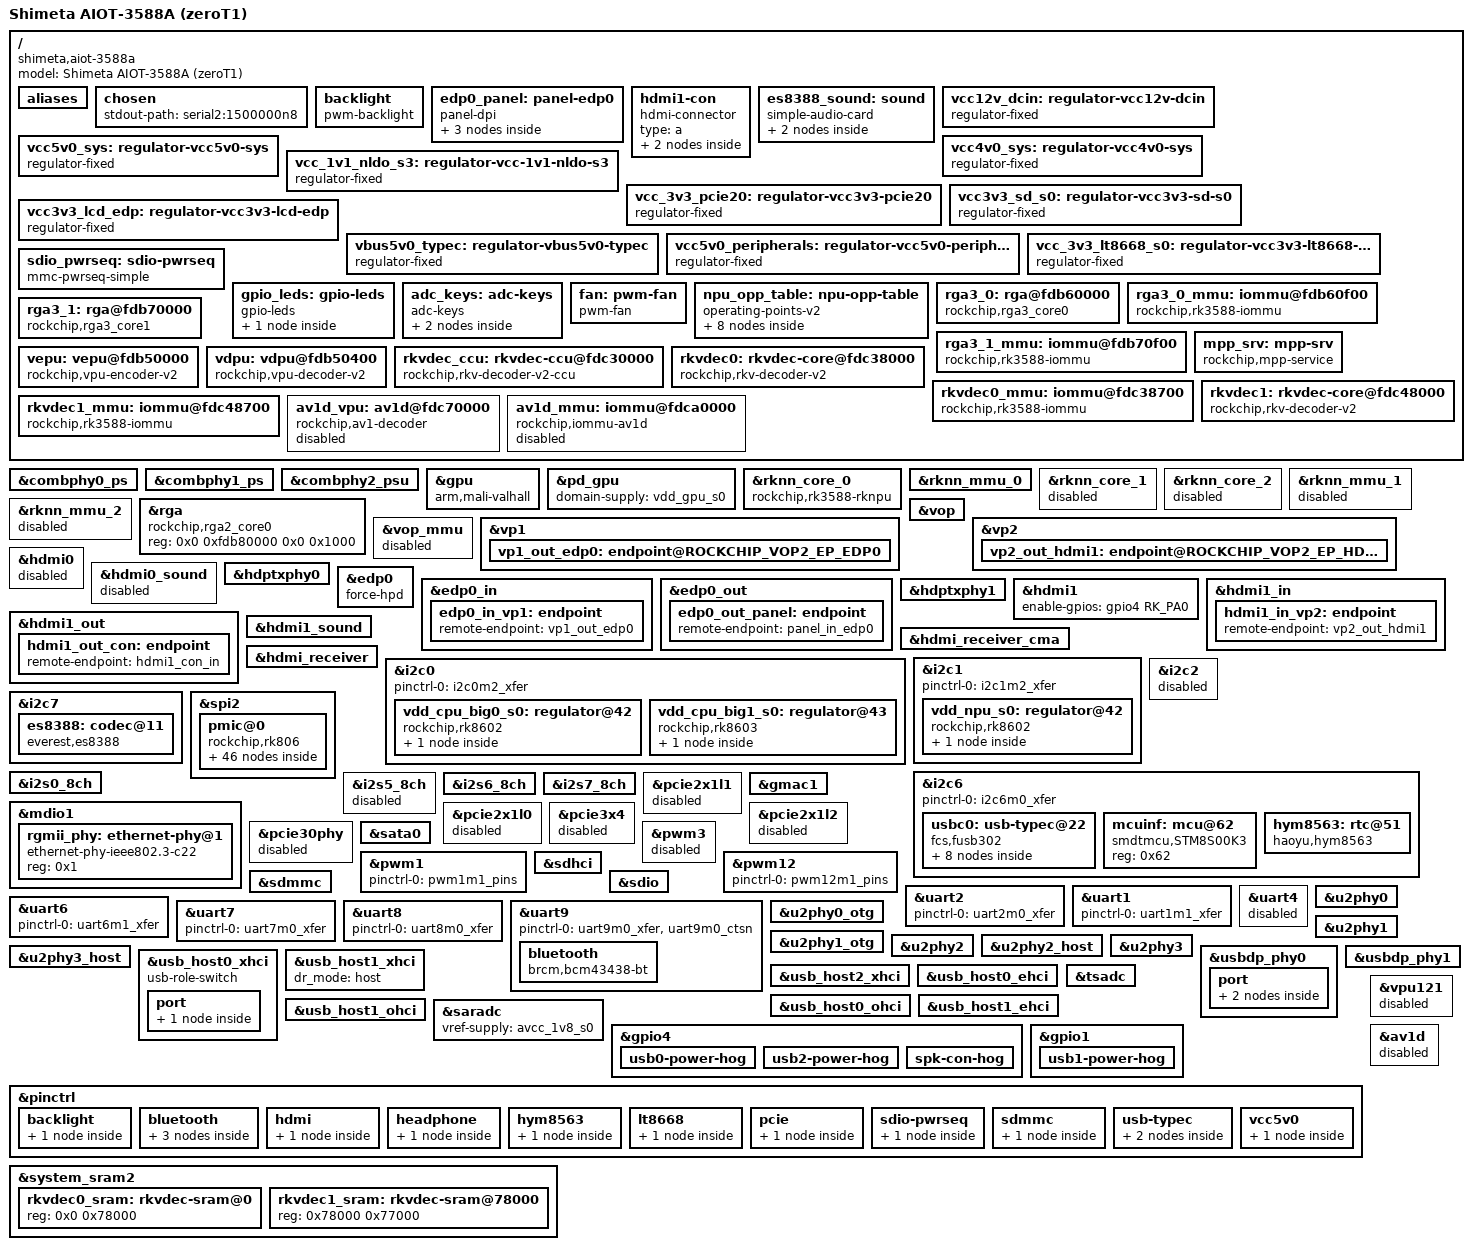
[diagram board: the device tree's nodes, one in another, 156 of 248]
// SPDX-License-Identifier: (GPL-2.0+ OR MIT)
/*
 * Shimeta（视美泰）AIOT-3588A / zeroT1 —— RK3588 板级设备树（fnOS / 上游内核版）
 *
 * 底稿：FriendlyElec NanoPC-T6 上游 DTS（Linux v6.18 的
 *       arch/arm64/boot/dts/rockchip/rk3588-nanopc-t6.dtsi），按硬件差异裁剪移植。
 *       引脚、GPIO、电源、面板时序等硬件事实取自视美泰原厂 2023 固件反编译树
 *       （RK BSP 6.1 的 rk3588-aiot3588a.dts），写法遵循上游 mainline 6.18。
 *
 * 与 NanoPC-T6 的主要差异（也是为什么不能直接用 nanopc-t6.dtb）：
 *  1. 主显示是 eDP 面板（1920x1080，139MHz / 2080x1111 厂商时序，实机刷新率
 *     60.15Hz；VOP dclk 实测 136.36MHz，详见 panel-timing 注释），不是 HDMI0：
 *     - eDP PHY = hdptxphy0（fed60000），HDMI0 与 eDP 共用这一颗 PHY，本板未用 HDMI0
 *     - eDP 控制器 edp0 -> VOP VP1；HDMI1 -> VOP VP2（不能走 VP0，理由见下）
 *     - 面板：GPIO2_C5 使能，vcc3v3_lcd_edp 供电，PWM1 背光（GPIO2_C1 使能，周期 20000ns）
 *  2. HDMI 输出走 HDMI1（hdptxphy1 / fed70000，GPIO4_A0 使能）-> VOP **VP2**
 *     - 2026-11-02 实测：HDMI1 走 VP0 时，只要 eDP 同时启用（eDP 占 VP1），
 *       HDMI 侧 PHY/时钟全部正常但显示器黑屏；改接 VP2 后双屏同时输出正常。
 *       （只开 eDP、HDMI 不接时 VP0 也能亮，属视频口复用冲突，不能作为定论。）
 *  3. HDMI IN：hdmi_receiver（fdee0000），HPD 检测脚 GPIO1_PD5
 *  4. 音频 codec 是 ES8388（i2c7 0x1b，i2s0_8ch），耳机检测 GPIO4_C2，
 *     扬声器功放使能 GPIO4_A3（低有效，用 gpio-hog 常开）
 *  5. WiFi/BT 是 AP6256：WiFi 走 SDIO（sdio_pwrseq GPIO0_PC4 复位），
 *     BT 走 uart9（reset GPIO0_PC6 / wake GPIO0_PC5 / host-wake GPIO0_PA0）
 *  6. 电源域不同：CPU 大核 i2c0（rk8602@42 / rk8603@43），NPU 在 i2c1（rk8602@42）
 *  7. 板载 SATA0（combphy0_ps）+ miniPCIe（pcie2x1l1 / fe180000 / combphy1_ps，
 *     reset GPIO1_PA7），2230 NVMe SSD 与 4G 模块共用 miniPCIe 座的不同通道
 *  8. 5 路业务串口：uart1/uart4/uart6/uart7/uart8（+ uart9 给蓝牙，uart2 调试）
 *  9. 板级电源：vcc5v0_peripherals（GPIO3_D5，必须 always-on）、
 *     vcc_3v3_lt8668_s0（GPIO4_PB6，HDMI 输出芯片供电，always-on）
 * 10. 无 IR 接收（原厂用 pwm3 的 remotectl 驱动，上游没有该驱动，此 DTS 未启用）
 *
 * 编译方式：作为 mainline 内核 arch/arm64/boot/dts/rockchip/ 下的文件，
 *   在 Makefile 的 dtb-y 里加 rk3588-aiot3588a.dtb 即可，随内核一起编译。
 */

/dts-v1/;

#include <dt-bindings/gpio/gpio.h>
#include <dt-bindings/input/input.h>
#include <dt-bindings/pinctrl/rockchip.h>
#include <dt-bindings/pwm/pwm.h>
#include <dt-bindings/soc/rockchip,vop2.h>
#include <dt-bindings/usb/pd.h>
#include "rk3588.dtsi"

/ {
	model = "Shimeta AIOT-3588A (zeroT1)";
	compatible = "shimeta,aiot-3588a", "rockchip,rk3588";

	aliases {
		mmc0 = &sdhci;
		mmc1 = &sdmmc;
		mmc2 = &sdio;
		/* 厂商 mpp_rkvdec2 驱动用 of_alias_get_id(np, "rkvdec") 取 core_id，
		 * core0 才会注册进 mpp service，所以别名必须有 */
		rkvdec0 = &rkvdec0;
		rkvdec1 = &rkvdec1;
	};

	chosen {
		stdout-path = "serial2:1500000n8";
	};

	/* ==================== 显示 ==================== */

	backlight: backlight {
		compatible = "pwm-backlight";
		pwms = <&pwm1 0 20000 0>;
		brightness-levels = <0 20 40 60 80 100 120 140 160 180 200 220 240 255>;
		default-brightness-level = <7>;
		enable-gpios = <&gpio2 RK_PC1 GPIO_ACTIVE_HIGH>;
		pinctrl-names = "default";
		pinctrl-0 = <&backlight_en>;
		status = "okay";
	};

	/*
	 * eDP 面板。fnOS 用的 mainline 6.18 内核里 panel-simple 驱动
	 * 已经删掉了通用 "simple-panel" compatible（只剩 "panel-dpi"），
	 * 且 eDP connector-type 会被显式拒绝（"eDP panels moved to panel-edp"）。
	 * 因此这里用 "panel-dpi"：panel_dpi_probe() 从 panel-timing 解析时序、
	 * connector 类型固定为 DPI（对 VOP->eDP 链路无影响，eDP connector 由
	 * rockchip-dp 自己创建），panel-simple 能正常 bind 并注册 drm_panel。
	 */
	edp0_panel: panel-edp0 {
		compatible = "panel-dpi";
		backlight = <&backlight>;
		power-supply = <&vcc3v3_lcd_edp>;
		enable-gpios = <&gpio2 RK_PC5 GPIO_ACTIVE_HIGH>;
		prepare-delay-ms = <120>;
		enable-delay-ms = <120>;
		unprepare-delay-ms = <120>;
		disable-delay-ms = <120>;
		width-mm = <129>;
		height-mm = <171>;
		bpc = <8>;
		status = "okay";

		panel-timing {
			/* 139MHz / 2080x1111 —— 面板厂商标称时序，2026-11-11 实机验证画面
			 * 正常，面板侧刷新率 60.15Hz（此前 132MHz 方案只有 57.12Hz）。
			 *
			 * VOP dclk 只能从 PLL 整数分频：实测 dclk_vop1 = 136.36MHz
			 * （1500MHz/11），并非精确 139MHz；但面板 TCON 按该时序工作正常。
			 * 历史：曾担心 VOP/TRX 的 MSA 时钟与实际像素时钟不一致，先用
			 * 132MHz（GPLL 1188/9）验证；也试过 132MHz/2000x1100（恰好 60Hz）
			 * —— 屏幕不出图，TCON 不接受该 porch。
			 * ⇒ clock-frequency 按标称 139MHz 写；porch 必须保持 2080x1111，
			 *   不要为凑刷新率改动。
			 */
			clock-frequency = <139000000>;
			hactive = <1920>;
			vactive = <1080>;
			hfront-porch = <40>;
			hsync-len = <20>;
			hback-porch = <100>;
			vfront-porch = <12>;
			vsync-len = <4>;
			vback-porch = <15>;
			hsync-active = <0>;
			vsync-active = <0>;
			de-active = <0>;
			pixelclk-active = <0>;
		};

		port {
			panel_in_edp0: endpoint {
				remote-endpoint = <&edp0_out_panel>;
			};
		};
	};

	hdmi1-con {
		compatible = "hdmi-connector";
		type = "a";

		port {
			hdmi1_con_in: endpoint {
				remote-endpoint = <&hdmi1_out_con>;
			};
		};
	};

	/* ==================== 音频 ==================== */

	es8388_sound: sound {
		compatible = "simple-audio-card";
		simple-audio-card,name = "rockchip-es8388";
		simple-audio-card,format = "i2s";
		simple-audio-card,mclk-fs = <256>;
		simple-audio-card,hp-det-gpios = <&gpio4 RK_PC2 GPIO_ACTIVE_HIGH>;
		pinctrl-names = "default";
		pinctrl-0 = <&hp_det>;
		/*
		 * es8328 驱动的 DAPM widget 只有 Headphone/Speaker 与
		 * LINPUT1/2、RINPUT1/2，没有 "Main Mic"/"MIC1" 这类名字；
		 * 写错会让 simple-audio-card 解析失败、整张声卡注册不了
		 * （日志：Failed to add route MIC1(*) -> Main Mic / -ENODEV）。
		 * 本板 NAS 场景只用播放，麦克风路由先不写。
		 */
		simple-audio-card,widgets =
			"Headphone", "Headphones",
			"Speaker", "Speaker";
		simple-audio-card,routing =
			"Headphones", "LOUT1",
			"Headphones", "ROUT1",
			"Speaker", "LOUT2",
			"Speaker", "ROUT2";

		simple-audio-card,cpu {
			sound-dai = <&i2s0_8ch>;
		};

		simple-audio-card,codec {
			sound-dai = <&es8388>;
		};
	};

	/* ==================== 电源 ==================== */

	vcc12v_dcin: regulator-vcc12v-dcin {
		compatible = "regulator-fixed";
		regulator-name = "vcc12v_dcin";
		regulator-always-on;
		regulator-boot-on;
		regulator-min-microvolt = <12000000>;
		regulator-max-microvolt = <12000000>;
	};

	/* vcc5v0_sys 供外设 */
	vcc5v0_sys: regulator-vcc5v0-sys {
		compatible = "regulator-fixed";
		regulator-name = "vcc5v0_sys";
		regulator-always-on;
		regulator-boot-on;
		regulator-min-microvolt = <5000000>;
		regulator-max-microvolt = <5000000>;
		vin-supply = <&vcc12v_dcin>;
	};

	/* vcc4v0_sys 供 RK806 / RK860x */
	vcc4v0_sys: regulator-vcc4v0-sys {
		compatible = "regulator-fixed";
		regulator-name = "vcc4v0_sys";
		regulator-always-on;
		regulator-boot-on;
		regulator-min-microvolt = <4000000>;
		regulator-max-microvolt = <4000000>;
		vin-supply = <&vcc12v_dcin>;
	};

	vcc_1v1_nldo_s3: regulator-vcc-1v1-nldo-s3 {
		compatible = "regulator-fixed";
		regulator-name = "vcc-1v1-nldo-s3";
		regulator-always-on;
		regulator-boot-on;
		regulator-min-microvolt = <1100000>;
		regulator-max-microvolt = <1100000>;
		vin-supply = <&vcc4v0_sys>;
	};

	/* miniPCIe 3.3V（常开，pcie2x1l1 的 vpcie3v3-supply） */
	vcc_3v3_pcie20: regulator-vcc3v3-pcie20 {
		compatible = "regulator-fixed";
		regulator-name = "vcc_3v3_pcie20";
		regulator-always-on;
		regulator-boot-on;
		regulator-min-microvolt = <3300000>;
		regulator-max-microvolt = <3300000>;
		vin-supply = <&vcc_3v3_s3>;
	};

	/*
	 * SD 卡 3.3V 电源，GPIO0_B7 控制。
	 * 硬件极性：低电平 = 上电（低有效）。2026-11-04 由 Android 侧（BSP 6.1 r27）
	 * 实机反证：官方 5.10 固件里该 regulator 从未被 enable、GPIO 保持低，卡工作正常；
	 * 之前这里写成 `enable-active-high` + GPIO_ACTIVE_HIGH，mmc 驱动在
	 * mmc_regulator_set_ocr() 里 regulator_enable() 会把 GPIO 拉高 = 断电，
	 * 于是 ACMD41 永远等不到 ready（`Card stuck being busy` / `error -110`）。
	 * 同时去掉 regulator-boot-on：让 mmc 驱动在 power up/off 时自己控制电源，
	 * 卡才能拿到干净的上电复位（Android 侧同样删除了 always-on/boot-on）。
	 */
	vcc3v3_sd_s0: regulator-vcc3v3-sd-s0 {
		compatible = "regulator-fixed";
		gpio = <&gpio0 RK_PB7 GPIO_ACTIVE_LOW>;
		pinctrl-names = "default";
		pinctrl-0 = <&sd_s0_pwr>;
		regulator-name = "vcc3v3_sd_s0";
		regulator-min-microvolt = <3300000>;
		regulator-max-microvolt = <3300000>;
		vin-supply = <&vcc_3v3_s3>;
	};

	/* eDP 面板 3.3V */
	vcc3v3_lcd_edp: regulator-vcc3v3-lcd-edp {
		compatible = "regulator-fixed";
		regulator-name = "vcc3v3_lcd_edp";
		regulator-always-on;
		regulator-boot-on;
		regulator-min-microvolt = <3300000>;
		regulator-max-microvolt = <3300000>;
		vin-supply = <&vcc_3v3_s3>;
	};

	/* USB-C 5V（fusb302 的 vbus-supply） */
	vbus5v0_typec: regulator-vbus5v0-typec {
		compatible = "regulator-fixed";
		enable-active-high;
		gpio = <&gpio4 RK_PA1 GPIO_ACTIVE_HIGH>;
		pinctrl-names = "default";
		pinctrl-0 = <&typec5v_pwren>;
		regulator-name = "vbus5v0_typec";
		regulator-min-microvolt = <5000000>;
		regulator-max-microvolt = <5000000>;
		vin-supply = <&vcc5v0_sys>;
	};

	/*
	 * 5V 外设（USB / 风扇 / 屏等）。原厂 GPIO3_D5 拉高才上电，
	 * 必须 always-on + boot-on，否则 eDP AUX 没应答（面板 5V 缺失）、
	 * USB 外设也不工作 —— 重构 DTS 时踩过的坑。
	 */
	vcc5v0_peripherals: regulator-vcc5v0-peripherals {
		compatible = "regulator-fixed";
		enable-active-high;
		gpio = <&gpio3 RK_PD5 GPIO_ACTIVE_HIGH>;
		pinctrl-names = "default";
		pinctrl-0 = <&vcc5v0_peripherals_en>;
		regulator-name = "vcc5v0_peripherals";
		regulator-always-on;
		regulator-boot-on;
		regulator-min-microvolt = <5000000>;
		regulator-max-microvolt = <5000000>;
		vin-supply = <&vcc5v0_sys>;
	};

	/* 显示输出芯片 LT8668 3.3V（GPIO4_PB6） */
	vcc_3v3_lt8668_s0: regulator-vcc3v3-lt8668-s0 {
		compatible = "regulator-fixed";
		enable-active-high;
		gpio = <&gpio4 RK_PB6 GPIO_ACTIVE_HIGH>;
		pinctrl-names = "default";
		pinctrl-0 = <&lt8668_pwren>;
		regulator-name = "vcc_3v3_lt8668_s0";
		regulator-always-on;
		regulator-boot-on;
		regulator-min-microvolt = <3300000>;
		regulator-max-microvolt = <3300000>;
		vin-supply = <&vcc_3v3_s3>;
	};

	/* ==================== WiFi / BT ==================== */

	sdio_pwrseq: sdio-pwrseq {
		compatible = "mmc-pwrseq-simple";
		clocks = <&hym8563>;
		clock-names = "ext_clock";
		pinctrl-names = "default";
		pinctrl-0 = <&wifi_enable_h>;
		post-power-on-delay-ms = <200>;
		reset-gpios = <&gpio0 RK_PC4 GPIO_ACTIVE_LOW>;
	};

	/* ==================== 按键 / 风扇 ==================== */

	/* 板载双色 LED：GPIO4_A5（高=蓝，低=红），默认常亮 */
	gpio_leds: gpio-leds {
		compatible = "gpio-leds";
		status = "okay";

		work_led: led-work {
			label = "zerot1:blue:work";
			linux,default-trigger = "default-on";
			gpios = <&gpio4 RK_PA5 GPIO_ACTIVE_HIGH>;
		};
	};

	adc_keys: adc-keys {
		compatible = "adc-keys";
		io-channels = <&saradc 1>;
		io-channel-names = "buttons";
		keyup-threshold-microvolt = <1800000>;
		poll-interval = <100>;

		vol-up-key {
			label = "volume up";
			linux,code = <KEY_VOLUMEUP>;
			press-threshold-microvolt = <17000>;
		};

		vol-down-key {
			label = "volume down";
			linux,code = <KEY_VOLUMEDOWN>;
			press-threshold-microvolt = <417000>;
		};
	};

	fan: pwm-fan {
		compatible = "pwm-fan";
		pwms = <&pwm12 0 50000 PWM_POLARITY_INVERTED>;
		cooling-levels = <0 102 170 230>;
		#cooling-cells = <2>;
		status = "okay";
	};
};

/* ==================== 时钟 / PHY ==================== */

&combphy0_ps {
	status = "okay";	/* SATA0 */
};

&combphy1_ps {
	status = "okay";	/* PCIe2x1l1 / miniPCIe */
};

&combphy2_psu {
	status = "okay";	/* USB3（usb_host2_xhci / fcd00000） */
};

/* ==================== GPU / NPU / RGA（厂商驱动适配） ====================
 * fnOS 6.18.18-trim 只带 Rockchip 厂商驱动模块：
 *   updates/trim/rk_gpu/mali.ko       → 期望 "arm,mali-valhall"
 *   updates/trim/rk_vcodec/rknpu.ko   → 期望 "rockchip,rk3588-rknpu"
 *   updates/trim/rk_vcodec/rga3.ko    → 期望 "rockchip,rga3_core0/1"、"rockchip,rga2_core0"
 * 上游 mainline 的 compatible（rockchip,rk3588-mali / rockchip,rk3588-rknn-core /
 * rockchip,rk3588-rga）在本内核里没有对应驱动，故按 fnOS 自带厂商 dtb
 * （usr/lib/linux-image-6.18.18-trim/rockchip/rk3588-nanopc-t6.dtb）改写成厂商形态。
 */

&gpu {
	/* 2026-11-11 用户选型：默认闭源 kbase（vendor 驱动，3D/Vulkan/OpenCL 强）。
	 * 开源 panthor 方案完整实现于 kernel-modules/panthor/ 与 58-kernel-sync 1b3 段；
	 * 如需切换：compatible 改为 "rockchip,rk3588-mali", "arm,mali-valhall-csf"
	 * 并删除下方 BSP interrupts/clocks（同时 40-xfce.sh 的 AccelMethod 改 glamor）。
	 * 闭源注意：Xorg glamor 不可用（libmali 无 X11 EGL 平台、无 EGL_EXT_platform_device），
	 * AccelMethod 必须 none（桌面 llvmpipe 软件渲染）；需在 fnOS 应用中心装
	 * Mali GPU Driver 才有闭源用户态库（libmali）。 */
	compatible = "arm,mali-valhall";
	interrupts = <GIC_SPI 94 IRQ_TYPE_LEVEL_HIGH 0>,
		     <GIC_SPI 93 IRQ_TYPE_LEVEL_HIGH 0>,
		     <GIC_SPI 92 IRQ_TYPE_LEVEL_HIGH 0>;
	interrupt-names = "GPU", "MMU", "JOB";
	clocks = <&scmi_clk SCMI_CLK_GPU>, <&cru CLK_GPU_COREGROUP>,
		 <&cru CLK_GPU_STACKS>, <&cru CLK_GPU>;
	clock-names = "clk_mali", "clk_gpu_coregroup",
		      "clk_gpu_stacks", "clk_gpu";
	mali-supply = <&vdd_gpu_s0>;
	/* 不要加 mem-supply：OPP 表是单路 3 值 opp-microvolt，两个 supply 会报
	 * "Invalid number of elements in microvolt property (3) with supplies (2)"
	 * 且 debugfs 里节点重名（vdd_gpu_s0 冲突）。mainline 只需 mali-supply。 */
	status = "okay";
};

&pd_gpu {
	domain-supply = <&vdd_gpu_s0>;
};

/* NPU：厂商 rknpu 驱动要求「三核合一」节点（pc/cna/core 三段 reg + 三个中断） */
&rknn_core_0 {
	compatible = "rockchip,rk3588-rknpu";
	/* 只映射每段低 0x9000：0x9000/0xa000 偏移处是 npu iommu 自身的寄存器
	 * （rknn_mmu_0 已注册 0xfdab9000/0xfdaba000/0xfdaca000/0xfdada000），
	 * 若这里按厂商的 0x10000 申请整段，fnOS 内核用 devm_ioremap_resource
	 * 会与之冲突报 "error -EBUSY: can't request region for resource"。
	 */
	reg = <0x0 0xfdab0000 0x0 0x9000>,
	      <0x0 0xfdac0000 0x0 0x9000>,
	      <0x0 0xfdad0000 0x0 0x9000>;
	reg-names = "pc", "cna", "core";
	operating-points-v2 = <&npu_opp_table>;
	opp-names = "npu";
	interrupts = <GIC_SPI 110 IRQ_TYPE_LEVEL_HIGH 0>,
		     <GIC_SPI 111 IRQ_TYPE_LEVEL_HIGH 0>,
		     <GIC_SPI 112 IRQ_TYPE_LEVEL_HIGH 0>;
	interrupt-names = "npu0_irq", "npu1_irq", "npu2_irq";
	clocks = <&scmi_clk SCMI_CLK_NPU>,
		 <&cru ACLK_NPU0>, <&cru ACLK_NPU1>, <&cru ACLK_NPU2>,
		 <&cru HCLK_NPU0>, <&cru HCLK_NPU1>, <&cru HCLK_NPU2>,
		 <&cru PCLK_NPU_ROOT>;
	clock-names = "clk_npu", "aclk0", "aclk1", "aclk2",
		      "hclk0", "hclk1", "hclk2", "pclk";
	assigned-clocks = <&scmi_clk SCMI_CLK_NPU>;
	assigned-clock-rates = <200000000>;
	resets = <&cru SRST_A_RKNN0>, <&cru SRST_A_RKNN1>, <&cru SRST_A_RKNN2>,
		 <&cru SRST_H_RKNN0>, <&cru SRST_H_RKNN1>, <&cru SRST_H_RKNN2>;
	reset-names = "srst_a0", "srst_a1", "srst_a2",
		      "srst_h0", "srst_h1", "srst_h2";
	power-domains = <&power RK3588_PD_NPUTOP>,
			<&power RK3588_PD_NPU1>,
			<&power RK3588_PD_NPU2>;
	power-domain-names = "npu0", "npu1", "npu2";
	iommus = <&rknn_mmu_0>;
	rknpu-supply = <&vdd_npu_s0>;
	mem-supply = <&vdd_npu_s0>;
	status = "okay";
};

/* 厂商形态：三核共用一个 IOMMU 块（4 段 reg、3 个中断） */
&rknn_mmu_0 {
	reg = <0x0 0xfdab9000 0x0 0x100>,
	      <0x0 0xfdaba000 0x0 0x100>,
	      <0x0 0xfdaca000 0x0 0x100>,
	      <0x0 0xfdada000 0x0 0x100>;
	interrupts = <GIC_SPI 110 IRQ_TYPE_LEVEL_HIGH 0>,
		     <GIC_SPI 111 IRQ_TYPE_LEVEL_HIGH 0>,
		     <GIC_SPI 112 IRQ_TYPE_LEVEL_HIGH 0>;
	interrupt-names = "npu0_mmu", "npu1_mmu", "npu2_mmu";
	status = "okay";
};

&rknn_core_1 {
	status = "disabled";
};

&rknn_core_2 {
	status = "disabled";
};

&rknn_mmu_1 {
	status = "disabled";
};

&rknn_mmu_2 {
	status = "disabled";
};

/* NPU OPP 表：fnOS 的 rknpu 0.9.8 必须从 DT 取 OPP，否则 probe 报
 * "failed to init opp info / failed to init_opp_table" 并放弃绑定（devfreq 不出现）。
 * 频率/电压取自厂商 5.10 反编译 dts（vdd_npu_s0 双 supply，min/target/max ×2）。
 */
/ {
	npu_opp_table: npu-opp-table {
		compatible = "operating-points-v2";

		opp-300000000 {
			opp-hz = /bits/ 64 <300000000>;
			opp-microvolt = <700000 700000 850000 700000 700000 850000>;
		};
		opp-400000000 {
			opp-hz = /bits/ 64 <400000000>;
			opp-microvolt = <700000 700000 850000 700000 700000 850000>;
		};
		opp-500000000 {
			opp-hz = /bits/ 64 <500000000>;
			opp-microvolt = <700000 700000 850000 700000 700000 850000>;
		};
		opp-600000000 {
			opp-hz = /bits/ 64 <600000000>;
			opp-microvolt = <700000 700000 850000 700000 700000 850000>;
		};
		opp-700000000 {
			opp-hz = /bits/ 64 <700000000>;
			opp-microvolt = <700000 700000 850000 700000 700000 850000>;
		};
		opp-800000000 {
			opp-hz = /bits/ 64 <800000000>;
			opp-microvolt = <750000 750000 850000 750000 750000 850000>;
		};
		opp-900000000 {
			opp-hz = /bits/ 64 <900000000>;
			opp-microvolt = <800000 800000 850000 800000 800000 850000>;
		};
		opp-1000000000 {
			opp-hz = /bits/ 64 <1000000000>;
			opp-microvolt = <850000 850000 850000 850000 850000 850000>;
		};
	};
};

/* RGA2：厂商 rga3.ko 内置 rga2_core0 支持 */
&rga {
	compatible = "rockchip,rga2_core0";
	reg = <0x0 0xfdb80000 0x0 0x1000>;
	clock-names = "aclk_rga2", "hclk_rga2", "clk_rga2";
	status = "okay";
};

/* ==================== 显示链路 ==================== */

/*
 * 显示链路（2026-10-26 实测修正）
 * fnOS 6.18 内核的 rockchipdrm 缺少 "Set VOP for the DRM DMA device" 补丁
 * （Collabora 分支 47c21077），fbdev/dumb buffer 会分配在错误的 dma 设备上，
 * VOP 平面寄存器里拿到的地址是 0 → 屏幕全黑（只有背光）。
 * 绕法：关掉 VOP 的 IOMMU，让 DMA 直接走物理地址（fb 缓冲在 32bit CMA 内）。
 */
&vop {
	/delete-property/ iommus;
	status = "okay";
};

&vop_mmu {
	status = "disabled";
};

/*
 * HDMI1 -> VP2（2026-11-02 实测定稿）
 * RK3588 上 HDMI1(VO1) 与 eDP0(VO0) 同时启用时，若 HDMI1 走 VP0、eDP 走 VP1
 * 则 HDMI 有 TMDS/PLL 但显示器无信号（黑屏）；把 HDMI1 改到 VP2、eDP 留 VP1
 * 后双屏同时正常。单开 eDP 时 HDMI1 走 VP0 也能亮，故这是视频口复用冲突。
 */
&vp2 {
	vp2_out_hdmi1: endpoint@ROCKCHIP_VOP2_EP_HDMI1 {
		reg = <ROCKCHIP_VOP2_EP_HDMI1>;
		remote-endpoint = <&hdmi1_in_vp2>;
	};
};

/* eDP -> VP1 */
&vp1 {
	vp1_out_edp0: endpoint@ROCKCHIP_VOP2_EP_EDP0 {
		reg = <ROCKCHIP_VOP2_EP_EDP0>;
		remote-endpoint = <&edp0_in_vp1>;
	};
};

/* HDMI0 与 eDP 共用 hdptxphy0（fed60000），本板不用 HDMI0 */
&hdmi0 {
	status = "disabled";
};

&hdmi0_sound {
	status = "disabled";
};

&hdptxphy0 {
	status = "okay";	/* 给 eDP */
};

&edp0 {
	/*
	 * 面板没有独立 HPD 信号，BSP 6.1 的 dtb 同样用 force-hpd；
	 * mainline analogix_dp 只在 HPD 检测失败时才用它强置 HPD_STATUS，
	 * 但按 RK3588 TRM：HPD_STATUS=0 时 AUX CH 不工作 ⇒ 保留该属性。
	 */
	force-hpd;
	status = "okay";
};

&edp0_in {
	edp0_in_vp1: endpoint {
		remote-endpoint = <&vp1_out_edp0>;
	};
};

&edp0_out {
	edp0_out_panel: endpoint {
		remote-endpoint = <&panel_in_edp0>;
	};
};

&hdptxphy1 {
	status = "okay";	/* 给 HDMI1 */
};

&hdmi1 {
	/* HDMI1 输出使能脚（Android 侧同为 GPIO4_A0，ACTIVE_HIGH）；mainline
	 * dw_hdmi_qp-rockchip 的 encoder_enable() 会 gpiod_set_value(1) 驱动它。 */
	enable-gpios = <&gpio4 RK_PA0 GPIO_ACTIVE_HIGH>;
	status = "okay";
};

&hdmi1_in {
	hdmi1_in_vp2: endpoint {
		remote-endpoint = <&vp2_out_hdmi1>;
	};
};

&hdmi1_out {
	hdmi1_out_con: endpoint {
		remote-endpoint = <&hdmi1_con_in>;
	};
};

/*
 * HDMI1 音频：用户要求保留 HDMI 音频输出，故显式启用（原厂生产 dtb 里
 * hdmi0_sound/hdmi1_sound 其实都是 disabled）。
 * 已知代价：没有接 HDMI 显示器时（无 EDID/ELD），hdmi-audio-codec 的
 * snd_soc_dai_prepare() 会返回 -ENODEV，PulseAudio 等用户态会反复尝试打开
 * 该声卡，dmesg 出现 "ASoC error (-19)" 刷屏；接上显示器后即恢复正常。
 * 如日后不需要 HDMI 音频、只想清静日志，把本节点改回 disabled 即可。
 */
&hdmi1_sound {
	status = "okay";
};

/* HDMI IN */
&hdmi_receiver_cma {
	status = "okay";
};

&hdmi_receiver {
	hpd-gpios = <&gpio1 RK_PD5 GPIO_ACTIVE_LOW>;
	pinctrl-names = "default";
	pinctrl-0 = <&hdmim1_rx_cec &hdmim1_rx_hpdin &hdmim1_rx_scl
		     &hdmim1_rx_sda &hdmirx_hpd>;
	status = "okay";
};

/* ==================== I2C ==================== */

/* CPU 大核电源 */
&i2c0 {
	pinctrl-names = "default";
	pinctrl-0 = <&i2c0m2_xfer>;
	status = "okay";

	vdd_cpu_big0_s0: regulator@42 {
		compatible = "rockchip,rk8602";
		reg = <0x42>;
		fcs,suspend-voltage-selector = <1>;
		regulator-name = "vdd_cpu_big0_s0";
		regulator-always-on;
		regulator-boot-on;
		regulator-min-microvolt = <550000>;
		regulator-max-microvolt = <1050000>;
		regulator-ramp-delay = <2300>;
		vin-supply = <&vcc4v0_sys>;

		regulator-state-mem {
			regulator-off-in-suspend;
		};
	};

	vdd_cpu_big1_s0: regulator@43 {
		compatible = "rockchip,rk8603", "rockchip,rk8602";
		reg = <0x43>;
		fcs,suspend-voltage-selector = <1>;
		regulator-name = "vdd_cpu_big1_s0";
		regulator-always-on;
		regulator-boot-on;
		regulator-min-microvolt = <550000>;
		regulator-max-microvolt = <1050000>;
		regulator-ramp-delay = <2300>;
		vin-supply = <&vcc4v0_sys>;

		regulator-state-mem {
			regulator-off-in-suspend;
		};
	};
};

/* NPU 电源（本板在 i2c1，NanoPC-T6 在 i2c2） */
&i2c1 {
	pinctrl-names = "default";
	pinctrl-0 = <&i2c1m2_xfer>;
	status = "okay";

	vdd_npu_s0: regulator@42 {
		compatible = "rockchip,rk8602";
		reg = <0x42>;
		fcs,suspend-voltage-selector = <1>;
		regulator-name = "vdd_npu_s0";
		regulator-always-on;
		regulator-boot-on;
		regulator-min-microvolt = <550000>;
		regulator-max-microvolt = <950000>;
		regulator-ramp-delay = <2300>;
		vin-supply = <&vcc4v0_sys>;

		regulator-state-mem {
			regulator-off-in-suspend;
		};
	};
};

&i2c2 {
	status = "disabled";
};

/* USB-C（fusb302）+ RTC（hym8563） */
&i2c6 {
	pinctrl-names = "default";
	pinctrl-0 = <&i2c6m0_xfer>;
	status = "okay";

	usbc0: usb-typec@22 {
		compatible = "fcs,fusb302";
		reg = <0x22>;
		interrupt-parent = <&gpio0>;
		interrupts = <RK_PD3 IRQ_TYPE_EDGE_FALLING>;
		int-n-gpios = <&gpio0 RK_PD3 GPIO_ACTIVE_LOW>;
		pinctrl-names = "default";
		pinctrl-0 = <&usbc0_int>;
		vbus-supply = <&vbus5v0_typec>;
		status = "okay";

		usbc0_con: connector {
			compatible = "usb-c-connector";
			data-role = "dual";
			label = "USB-C";
			op-sink-microwatt = <1000000>;
			power-role = "dual";
			sink-pdos = <PDO_FIXED(5000, 3000, PDO_FIXED_USB_COMM)>;
			source-pdos = <PDO_FIXED(5000, 2000, PDO_FIXED_USB_COMM)>;
			/* 原厂为 sink：板子默认从 Type-C 取电、作为 device 端，
			 * 接 PC 时才能被枚举成 adb 设备。 */
			try-power-role = "sink";

			ports {
				#address-cells = <1>;
				#size-cells = <0>;

				port@0 {
					reg = <0>;
					usbc0_ss: endpoint {
						remote-endpoint = <&usbdp_phy0_typec_ss>;
					};
				};

				port@1 {
					reg = <1>;
					usbc0_sbu: endpoint {
						remote-endpoint = <&usbdp_phy0_typec_sbu>;
					};
				};

				/* Type-C 角色切换（host/device）必须挂在本 connector
				 * 节点下面：fusb302 驱动（fusb302_fwnode_get）把
				 * tcpm 设备的 fwnode 指向 connector 子节点，tcpm 再通过
				 * connector 的 graph 端点找 dwc3 的 usb-role-switch。
				 * 端点挂在 usb-typec@22 节点本身下时 tcpm 找不到
				 * role switch（port->role_sw = NULL），只会更新
				 * /sys/class/typec/port0/data_role 而不真正切换 dwc3，
				 * 这也是此前只能靠用户态脚本写 debugfs mode 的原因。
				 * 注：usb_role 的 sysfs role 文件不存在属正常现象——
				 * dwc3 注册 role switch 时未设 allow_userspace_control。
				 */
				port@2 {
					reg = <2>;
					usbc0_role_sw: endpoint {
						remote-endpoint = <&usb_host0_xhci_drd_sw>;
					};
				};
			};
		};
	};

	/* 板载 MCU（STM8S00K3）：负责喂硬件看门狗、蜂鸣器等；
	 * 不喂狗时 MCU 约 603s 后复位 SoC（以前"无故重启"就是它）。
	 * 驱动见 patches/kernel/0001-add-smdt-mcu-watchdog.patch，
	 * 预编译模块 assets/modules/6.18.18-trim/smdt_mcu_wdt.ko。
	 */
	mcuinf: mcu@62 {
		compatible = "smdtmcu,STM8S00K3";
		reg = <0x62>;
		#pwm-cells = <2>;
	};

	hym8563: rtc@51 {
		compatible = "haoyu,hym8563";
		reg = <0x51>;
		#clock-cells = <0>;
		clock-output-names = "hym8563";
		pinctrl-names = "default";
		pinctrl-0 = <&hym8563_int>;
		interrupt-parent = <&gpio0>;
		interrupts = <RK_PB0 IRQ_TYPE_LEVEL_LOW>;
		wakeup-source;
	};
};

/* 音频 codec ES8388 */
&i2c7 {
	pinctrl-names = "default";
	pinctrl-0 = <&i2c7m0_xfer>;
	clock-frequency = <200000>;
	status = "okay";

	/*
	 * 实测 I2C 地址是 0x11（原厂 BSP DTS es8388@11，Android 上是 7-0011）。
	 * 之前写成 0x1b，codec 能"注册"但所有寄存器读写都 -ENXIO：
	 *   es8328 7-001b: ASoC error (-6): at snd_soc_component_update_bits() ...
	 * 驱动用 mainline 的 es8328（上游对 ES8328/ES8388 共用的驱动，
	 * 原厂 BSP 里叫 es8323，功能等价），compatible "everest,es8388" 即可。
	 */
	es8388: codec@11 {
		compatible = "everest,es8388";
		reg = <0x11>;
		clocks = <&cru I2S0_8CH_MCLKOUT>;
		clock-names = "mclk";
		#sound-dai-cells = <0>;
		assigned-clocks = <&cru I2S0_8CH_MCLKOUT>;
		assigned-clock-rates = <12288000>;
	};
};

/* ==================== PMIC（RK806，走 SPI2） ==================== */

&spi2 {
	status = "okay";
	assigned-clocks = <&cru CLK_SPI2>;
	assigned-clock-rates = <200000000>;
	pinctrl-names = "default";
	pinctrl-0 = <&spi2m2_cs0 &spi2m2_pins>;
	num-cs = <1>;

	pmic@0 {
		compatible = "rockchip,rk806";
		spi-max-frequency = <1000000>;
		reg = <0x0>;

		interrupt-parent = <&gpio0>;
		interrupts = <7 IRQ_TYPE_LEVEL_LOW>;

		pinctrl-names = "default";
		pinctrl-0 = <&pmic_pins>, <&rk806_dvs1_null>,
			    <&rk806_dvs2_null>, <&rk806_dvs3_null>;

		system-power-controller;

		/* RK806 复位模式：1 = RESET（整板复位，与厂商 pmic-reset-func=<1> 一致）。
		 * 本板（mainline u-boot v2026.10 + 内核 6.18.18）实测三种取值：
		 *   RST_FUN=2（u-boot 无该属性时默认写 RESET_NOTIFY）→ warm reboot 挂死；
		 *   RST_FUN=0（RESTART PMU，上游 tiger/jaguar 用的值）→ 同样挂死，只能断电；
		 *   RST_FUN=1 → 能重启，但 BL31→PMIC 复位路径耗时约 86s
		 *              （systemd 关机只花 4s，慢在复位；已排除 systemd stop job 与 MCU 看门狗）。
		 * 故仍需 56-fast-reboot.sh 的 CRU GLB_SRST_FST 钩子，把整次重启压到 ~15s。
		 * 内核 rk8xx-core.c 原生支持该属性，不再需要 rk806_rstfix.ko。 */
		rockchip,reset-mode = <1>;

		vcc1-supply = <&vcc4v0_sys>;
		vcc2-supply = <&vcc4v0_sys>;
		vcc3-supply = <&vcc4v0_sys>;
		vcc4-supply = <&vcc4v0_sys>;
		vcc5-supply = <&vcc4v0_sys>;
		vcc6-supply = <&vcc4v0_sys>;
		vcc7-supply = <&vcc4v0_sys>;
		vcc8-supply = <&vcc4v0_sys>;
		vcc9-supply = <&vcc4v0_sys>;
		vcc10-supply = <&vcc4v0_sys>;
		vcc11-supply = <&vcc_2v0_pldo_s3>;
		vcc12-supply = <&vcc4v0_sys>;
		vcc13-supply = <&vcc_1v1_nldo_s3>;
		vcc14-supply = <&vcc_1v1_nldo_s3>;
		vcca-supply = <&vcc4v0_sys>;

		gpio-controller;
		#gpio-cells = <2>;

		rk806_dvs1_null: dvs1-null-pins {
			pins = "gpio_pwrctrl1";
			function = "pin_fun0";
		};

		rk806_dvs2_null: dvs2-null-pins {
			pins = "gpio_pwrctrl2";
			function = "pin_fun0";
		};

		rk806_dvs3_null: dvs3-null-pins {
			pins = "gpio_pwrctrl3";
			function = "pin_fun0";
		};

		regulators {
			vdd_gpu_s0: vdd_gpu_mem_s0: dcdc-reg1 {
				regulator-boot-on;
				regulator-min-microvolt = <550000>;
				regulator-max-microvolt = <950000>;
				regulator-ramp-delay = <12500>;
				regulator-name = "vdd_gpu_s0";
				regulator-enable-ramp-delay = <400>;

				regulator-state-mem {
					regulator-off-in-suspend;
				};
			};

			vdd_cpu_lit_s0: vdd_cpu_lit_mem_s0: dcdc-reg2 {
				regulator-always-on;
				regulator-boot-on;
				regulator-min-microvolt = <550000>;
				regulator-max-microvolt = <950000>;
				regulator-ramp-delay = <12500>;
				regulator-name = "vdd_cpu_lit_s0";

				regulator-state-mem {
					regulator-off-in-suspend;
				};
			};

			vdd_log_s0: dcdc-reg3 {
				regulator-always-on;
				regulator-boot-on;
				regulator-min-microvolt = <675000>;
				regulator-max-microvolt = <750000>;
				regulator-ramp-delay = <12500>;
				regulator-name = "vdd_log_s0";

				regulator-state-mem {
					regulator-off-in-suspend;
					regulator-suspend-microvolt = <750000>;
				};
			};

			vdd_vdenc_s0: vdd_vdenc_mem_s0: dcdc-reg4 {
				regulator-always-on;
				regulator-boot-on;
				regulator-min-microvolt = <550000>;
				regulator-max-microvolt = <950000>;
				regulator-ramp-delay = <12500>;
				regulator-name = "vdd_vdenc_s0";

				regulator-state-mem {
					regulator-off-in-suspend;
				};
			};

			vdd_ddr_s0: dcdc-reg5 {
				regulator-always-on;
				regulator-boot-on;
				regulator-min-microvolt = <675000>;
				regulator-max-microvolt = <900000>;
				regulator-ramp-delay = <12500>;
				regulator-name = "vdd_ddr_s0";

				regulator-state-mem {
					regulator-off-in-suspend;
					regulator-suspend-microvolt = <850000>;
				};
			};

			vdd2_ddr_s3: dcdc-reg6 {
				regulator-always-on;
				regulator-boot-on;
				regulator-name = "vdd2_ddr_s3";

				regulator-state-mem {
					regulator-on-in-suspend;
				};
			};

			vcc_2v0_pldo_s3: dcdc-reg7 {
				regulator-always-on;
				regulator-boot-on;
				regulator-min-microvolt = <2000000>;
				regulator-max-microvolt = <2000000>;
				regulator-ramp-delay = <12500>;
				regulator-name = "vdd_2v0_pldo_s3";

				regulator-state-mem {
					regulator-on-in-suspend;
					regulator-suspend-microvolt = <2000000>;
				};
			};

			vcc_3v3_s3: dcdc-reg8 {
				regulator-always-on;
				regulator-boot-on;
				regulator-min-microvolt = <3300000>;
				regulator-max-microvolt = <3300000>;
				regulator-name = "vcc_3v3_s3";

				regulator-state-mem {
					regulator-on-in-suspend;
					regulator-suspend-microvolt = <3300000>;
				};
			};

			vddq_ddr_s0: dcdc-reg9 {
				regulator-always-on;
				regulator-boot-on;
				regulator-name = "vddq_ddr_s0";

				regulator-state-mem {
					regulator-off-in-suspend;
				};
			};

			vcc_1v8_s3: dcdc-reg10 {
				regulator-always-on;
				regulator-boot-on;
				regulator-min-microvolt = <1800000>;
				regulator-max-microvolt = <1800000>;
				regulator-name = "vcc_1v8_s3";

				regulator-state-mem {
					regulator-on-in-suspend;
					regulator-suspend-microvolt = <1800000>;
				};
			};

			avcc_1v8_s0: pldo-reg1 {
				regulator-always-on;
				regulator-boot-on;
				regulator-min-microvolt = <1800000>;
				regulator-max-microvolt = <1800000>;
				regulator-name = "avcc_1v8_s0";

				regulator-state-mem {
					regulator-off-in-suspend;
				};
			};

			vcc_1v8_s0: pldo-reg2 {
				regulator-always-on;
				regulator-boot-on;
				regulator-min-microvolt = <1800000>;
				regulator-max-microvolt = <1800000>;
				regulator-name = "vcc_1v8_s0";

				regulator-state-mem {
					regulator-off-in-suspend;
					regulator-suspend-microvolt = <1800000>;
				};
			};

			avdd_1v2_s0: pldo-reg3 {
				regulator-always-on;
				regulator-boot-on;
				regulator-min-microvolt = <1200000>;
				regulator-max-microvolt = <1200000>;
				regulator-name = "avdd_1v2_s0";

				regulator-state-mem {
					regulator-off-in-suspend;
				};
			};

			vcc_3v3_s0: pldo-reg4 {
				regulator-always-on;
				regulator-boot-on;
				regulator-min-microvolt = <3300000>;
				regulator-max-microvolt = <3300000>;
				regulator-ramp-delay = <12500>;
				regulator-name = "vcc_3v3_s0";

				regulator-state-mem {
					regulator-off-in-suspend;
				};
			};

			vccio_sd_s0: pldo-reg5 {
				regulator-always-on;
				regulator-boot-on;
				regulator-min-microvolt = <1800000>;
				regulator-max-microvolt = <3300000>;
				regulator-ramp-delay = <12500>;
				regulator-name = "vccio_sd_s0";

				regulator-state-mem {
					regulator-off-in-suspend;
				};
			};

			pldo6_s3: pldo-reg6 {
				regulator-always-on;
				regulator-boot-on;
				regulator-min-microvolt = <1800000>;
				regulator-max-microvolt = <1800000>;
				regulator-name = "pldo6_s3";

				regulator-state-mem {
					regulator-on-in-suspend;
					regulator-suspend-microvolt = <1800000>;
				};
			};

			vdd_0v75_s3: nldo-reg1 {
				regulator-always-on;
				regulator-boot-on;
				regulator-min-microvolt = <750000>;
				regulator-max-microvolt = <750000>;
				regulator-name = "vdd_0v75_s3";

				regulator-state-mem {
					regulator-on-in-suspend;
					regulator-suspend-microvolt = <750000>;
				};
			};

			vdd_ddr_pll_s0: nldo-reg2 {
				regulator-always-on;
				regulator-boot-on;
				regulator-min-microvolt = <850000>;
				regulator-max-microvolt = <850000>;
				regulator-name = "vdd_ddr_pll_s0";

				regulator-state-mem {
					regulator-off-in-suspend;
					regulator-suspend-microvolt = <850000>;
				};
			};

			avdd_0v75_s0: nldo-reg3 {
				regulator-always-on;
				regulator-boot-on;
				regulator-min-microvolt = <750000>;
				regulator-max-microvolt = <750000>;
				regulator-name = "avdd_0v75_s0";

				regulator-state-mem {
					regulator-off-in-suspend;
				};
			};

			vdd_0v85_s0: nldo-reg4 {
				regulator-always-on;
				regulator-boot-on;
				regulator-min-microvolt = <850000>;
				regulator-max-microvolt = <850000>;
				regulator-name = "vdd_0v85_s0";

				regulator-state-mem {
					regulator-off-in-suspend;
				};
			};

			vdd_0v75_s0: nldo-reg5 {
				regulator-always-on;
				regulator-boot-on;
				regulator-min-microvolt = <750000>;
				regulator-max-microvolt = <750000>;
				regulator-name = "vdd_0v75_s0";

				regulator-state-mem {
					regulator-off-in-suspend;
				};
			};
		};
	};
};

/* ==================== I2S ==================== */

&i2s0_8ch {
	pinctrl-names = "default";
	pinctrl-0 = <&i2s0_lrck &i2s0_mclk &i2s0_sclk &i2s0_sdi0 &i2s0_sdo0>;
	status = "okay";
};

/* HDMI0 音频（HDMI0 未用，可关） */
&i2s5_8ch {
	status = "disabled";
};

/* HDMI1 音频 */
&i2s6_8ch {
	status = "okay";
};

/* HDMI IN 音频 */
&i2s7_8ch {
	status = "okay";
};

/* ==================== PCIe / SATA ==================== */

/* miniPCIe（2230 NVMe SSD / 4G 模块的 PCIe 通道） */
&pcie2x1l1 {
	/*
	 * 实测本板 miniPCIe 座只连通 USB 通道，PCIe 差分对未连出（插 4G 模块靠 USB）。
	 * 上游 dw-rockchip 驱动在无设备时 async probe 会一直等 link，导致内核卡住，
	 * 因此直接关闭。
	 */
	reset-gpios = <&gpio1 RK_PA7 GPIO_ACTIVE_HIGH>;
	vpcie3v3-supply = <&vcc_3v3_pcie20>;
	pinctrl-names = "default";
	pinctrl-0 = <&pcie2_1_rst>;
	status = "disabled";
};

/* ==================== 以太网（GMAC1） ==================== */

/*
 * 板载千兆网：RK3588 GMAC1 (fe1c0000) + RTL8211 类 PHY（MDIO 地址 1）。
 * 取值与原厂 BSP：rgmii-rxid、tx_delay 0x43、PHY 复位 GPIO3_B7（低有效）。
 * fnOS 内核的 dwmac-rk 是模块，靠 of modalias 自动加载。
 */
&gmac1 {
	phy-mode = "rgmii-rxid";
	clock_in_out = "output";
	snps,reset-gpios = <&gpio3 RK_PB7 GPIO_ACTIVE_LOW>;
	snps,reset-delays-us = <0 20000 100000>;
	pinctrl-names = "default";
	pinctrl-0 = <&gmac1_miim &gmac1_tx_bus2 &gmac1_rx_bus2
		     &gmac1_rgmii_clk &gmac1_rgmii_bus>;
	tx_delay = <0x43>;
	rx_delay = <0x10>;
	phy-handle = <&rgmii_phy>;
	status = "okay";
};

&mdio1 {
	rgmii_phy: ethernet-phy@1 {
		compatible = "ethernet-phy-ieee802.3-c22";
		reg = <0x1>;
	};
};

/* PCIe2x1l0 与 SATA0 共用 combphy0_ps（本板 SATA 在用），关掉 */
&pcie2x1l0 {
	status = "disabled";
};

/* PCIe2x1l2 与 USB3（usb_host2_xhci）共用 combphy2_psu，关掉 */
&pcie2x1l2 {
	status = "disabled";
};

&pcie30phy {
	status = "disabled";
};

&pcie3x4 {
	status = "disabled";
};

&sata0 {
	status = "okay";
};

/* ==================== PWM ==================== */

/* 背光 */
/* 背光 PWM1 必须用 m1 引脚组（GPIO1_PD3）。实测：用 m0（GPIO0_PC0）时
 * PWM 寄存器正常输出占空比，但屏幕完全无背光（该脚未连到背光电路，
 * 厂商 dtb 里的 m0 配置对应的是另一种屏幕 SKU）。
 * 注意：m1 与 uart4m0 的 TX 脚重叠，开机会有 4 行 uart4 pin 申请失败的
 * 警告，属已知且无害（原可用镜像同样如此）。 */
&pwm1 {
	pinctrl-names = "default";
	pinctrl-0 = <&pwm1m1_pins>;
	status = "okay";
};

/* 原厂 IR 用 pwm3（remotectl），上游无此驱动，暂不启用 */
&pwm3 {
	status = "disabled";
};

/* 风扇 */
&pwm12 {
	pinctrl-names = "default";
	pinctrl-0 = <&pwm12m1_pins>;
	status = "okay";
};

/* ==================== 存储 ==================== */

&sdhci {
	bus-width = <8>;
	no-sdio;
	no-sd;
	non-removable;
	max-frequency = <200000000>;
	mmc-hs400-1_8v;
	mmc-hs400-enhanced-strobe;
	status = "okay";
};

&sdmmc {
	bus-width = <4>;
	cap-mmc-highspeed;
	cap-sd-highspeed;
	cd-gpios = <&gpio0 RK_PA4 GPIO_ACTIVE_LOW>;
	disable-wp;
	no-mmc;
	no-sdio;
	sd-uhs-sdr104;
	vmmc-supply = <&vcc3v3_sd_s0>;
	vqmmc-supply = <&vccio_sd_s0>;
	status = "okay";
};

/* WiFi SDIO */
&sdio {
	/*
	 * WiFi(AP6256) 的 SDIO 走 m0 引脚组（GPIO2_A6/A7/B0/B1 + B2/B3），
	 * 这是 BSP 6.1 dtb 的用法；mainline 默认的 sdiom1 是 GPIO3_A0~A5，
	 * 与本板 gmac1 RGMII 复用冲突（启动日志：
	 * "pin gpio3-5 already requested by fe1c0000.ethernet; cannot claim for fe2d0000.mmc"），
	 * 会导致 sdio 起不来、没有 wlan0。
	 */
	pinctrl-names = "default";
	pinctrl-0 = <&sdiom0_pins>;
	bus-width = <4>;
	cap-sd-highspeed;
	cap-sdio-irq;
	keep-power-in-suspend;
	max-frequency = <150000000>;
	mmc-pwrseq = <&sdio_pwrseq>;
	no-mmc;
	no-sd;
	non-removable;
	sd-uhs-sdr104;
	status = "okay";
};

/* ==================== 串口 ==================== */

/* 调试口（uart2 -> ttyFIQ0 由 bootargs 指定，这里保持可用） */
&uart2 {
	pinctrl-names = "default";
	pinctrl-0 = <&uart2m0_xfer>;
	status = "okay";
};

/* 业务串口 TTL-1 */
&uart1 {
	pinctrl-names = "default";
	pinctrl-0 = <&uart1m1_xfer>;
	status = "okay";
};

/*
 * 业务串口 TTL-2：无法与背光 PWM 共存
 * uart4m0_xfer 的 TX 脚 = GPIO1_D3（pin 59），而本板背光 PWM1 实际走
 * pwm1m1_pins = GPIO1_D3（见下方 &pwm1 注释）。两者抢同一根脚，谁后申请
 * 谁失败：开背光就必然让 uart4 probe 报 "could not request pin 59"。
 * 2026-10-29 起直接 disabled，既保证背光（eDP 可用）又消掉日志刷屏。
 * 若将来改用 m0 背光方案的硬件版本，再把这里改回 okay。
 */
&uart4 {
	status = "disabled";
};

/* 业务串口 RS232-4 */
&uart6 {
	pinctrl-names = "default";
	pinctrl-0 = <&uart6m1_xfer>;
	status = "okay";
};

/* 业务串口 RS232-5 */
&uart7 {
	pinctrl-names = "default";
	pinctrl-0 = <&uart7m0_xfer>;
	status = "okay";
};

/* 业务串口 RS485-3 */
&uart8 {
	pinctrl-names = "default";
	pinctrl-0 = <&uart8m0_xfer>;
	status = "okay";
};

/* 蓝牙（AP6256 / BCM4345C0，走 serdev） */
&uart9 {
	pinctrl-names = "default";
	pinctrl-0 = <&uart9m0_xfer &uart9m0_ctsn>;
	status = "okay";

	bluetooth {
		compatible = "brcm,bcm43438-bt";
		clocks = <&hym8563>;
		clock-names = "lpo";
		interrupt-parent = <&gpio0>;
		interrupts = <RK_PA0 IRQ_TYPE_LEVEL_HIGH>;
		interrupt-names = "host-wakeup";
		device-wakeup-gpios = <&gpio0 RK_PC5 GPIO_ACTIVE_HIGH>;
		host-wakeup-gpios = <&gpio0 RK_PA0 GPIO_ACTIVE_HIGH>;
		reset-gpios = <&gpio0 RK_PC6 GPIO_ACTIVE_LOW>;
		/* 注意：不能写 shutdown-gpios —— 它和 reset-gpios 是同一个 GPIO0_PC6，
		 * hci_bcm 会分别请求两次，第二次返回 -EBUSY，导致 probe 失败（2026-10-28 实测）。
		 * 主线的 bcm 驱动用 reset-gpios 就够了。*/
		max-speed = <1500000>;
		vcc-supply = <&vcc_3v3_s0>;
	};
};

/* ==================== USB ==================== */

&u2phy0 {
	status = "okay";
};

&u2phy0_otg {
	status = "okay";
};

&u2phy1 {
	status = "okay";
};

&u2phy1_otg {
	status = "okay";
};

&u2phy2 {
	status = "okay";
};

&u2phy2_host {
	status = "okay";
};

&u2phy3 {
	status = "okay";
};

&u2phy3_host {
	status = "okay";
};

&usbdp_phy0 {
	mode-switch;
	orientation-switch;
	sbu1-dc-gpios = <&gpio4 RK_PA6 GPIO_ACTIVE_HIGH>;
	sbu2-dc-gpios = <&gpio4 RK_PA7 GPIO_ACTIVE_HIGH>;
	status = "okay";

	port {
		#address-cells = <1>;
		#size-cells = <0>;

		usbdp_phy0_typec_ss: endpoint@0 {
			reg = <0>;
			remote-endpoint = <&usbc0_ss>;
		};

		usbdp_phy0_typec_sbu: endpoint@1 {
			reg = <1>;
			remote-endpoint = <&usbc0_sbu>;
		};
	};
};

&usbdp_phy1 {
	/* 原厂 DTS 误把 Type-C VBUS 输出（vbus5v0_typec）当成 PHY 供电。
	 * PHY 电源来自 SoC 内部 PMIC，phy-supply 会在 power_on 时打开
	 * Type-C VBUS 5V，导致 fusb302 VBUSOK=1、tcpm 认为 vbus_vsafe0v=false，
	 * U 盘（sink）插入后卡在 SRC_ATTACH_WAIT 无法切 host。
	 * 删除该绑定，VBUS 改由 tcpm 在 SRC_ATTACHED 时通过 fusb302 控制。 */
	status = "okay";
};

&usb_host0_xhci {
	/* 正常（host/otg）模式。接 PC 需要 adb 时用 usbdev 变体 dtb：
	 * dts/mainline-6.18/rk3588-aiot3588a-usbdev.dts（dr_mode=peripheral）。 */
	usb-role-switch;
	status = "okay";

	port {
		#address-cells = <1>;
		#size-cells = <0>;

		usb_host0_xhci_drd_sw: endpoint@0 {
			reg = <0>;
			remote-endpoint = <&usbc0_role_sw>;
		};
	};
};

&usb_host1_xhci {
	dr_mode = "host";
	status = "okay";
};

&usb_host2_xhci {
	status = "okay";
};

&usb_host0_ehci {
	status = "okay";
};

&usb_host0_ohci {
	status = "okay";
};

&usb_host1_ehci {
	status = "okay";
};

&usb_host1_ohci {
	status = "okay";
};

/* ==================== 温度 / ADC ==================== */

&saradc {
	vref-supply = <&avcc_1v8_s0>;
	status = "okay";
};

&tsadc {
	status = "okay";
};

/* ==================== GPIO hog ==================== */

/* 3 路 USB 端口供电 GPIO（必须上电拉高，否则 USB 设备不上电） */
&gpio4 {
	usb0-power-hog {
		gpio-hog;
		gpios = <RK_PA2 GPIO_ACTIVE_HIGH>;
		output-high;
		line-name = "usb0-power";
	};

	usb2-power-hog {
		gpio-hog;
		gpios = <RK_PC6 GPIO_ACTIVE_HIGH>;
		output-high;
		line-name = "usb2-power";
	};

	/*
	 * 扬声器功放使能（GPIO4_A3，低电平使能，常开）
	 * 注意：这里必须写 output-high —— 该脚声明为 GPIO_ACTIVE_LOW，
	 * gpio-hog 的 output-* 用的是"逻辑电平"，output-high(逻辑1) 才会把
	 * 物理电平拉低 → 功放打开。写 output-low 时实测 debugfs 显示
	 * "out hi ACTIVE LOW"，物理为高 = 功放关 → 喇叭无声（2026-10-28 踩坑）。
	 */
	spk-con-hog {
		gpio-hog;
		gpios = <RK_PA3 GPIO_ACTIVE_LOW>;
		output-high;
		line-name = "spk-con";
	};
};

&gpio1 {
	usb1-power-hog {
		gpio-hog;
		gpios = <RK_PB1 GPIO_ACTIVE_HIGH>;
		output-high;
		line-name = "usb1-power";
	};
};

/* ==================== pinctrl ==================== */

&pinctrl {
	backlight {
		backlight_en: backlight-en {
			rockchip,pins = <2 RK_PC1 RK_FUNC_GPIO &pcfg_pull_none>;
		};
	};

	bluetooth {
		bt_reset_gpio: bt-reset-gpio {
			rockchip,pins = <0 RK_PC6 RK_FUNC_GPIO &pcfg_pull_none>;
		};

		bt_wake_gpio: bt-wake-gpio {
			rockchip,pins = <0 RK_PC5 RK_FUNC_GPIO &pcfg_pull_none>;
		};

		bt_irq_gpio: bt-irq-gpio {
			rockchip,pins = <0 RK_PA0 RK_FUNC_GPIO &pcfg_pull_down>;
		};
	};

	hdmi {
		hdmirx_hpd: hdmirx-hpd {
			rockchip,pins = <1 RK_PD5 RK_FUNC_GPIO &pcfg_pull_none>;
		};
	};

	headphone {
		hp_det: hp-det {
			rockchip,pins = <4 RK_PC2 RK_FUNC_GPIO &pcfg_pull_none>;
		};
	};

	hym8563 {
		hym8563_int: hym8563-int {
			rockchip,pins = <0 RK_PB0 RK_FUNC_GPIO &pcfg_pull_up>;
		};
	};

	lt8668 {
		lt8668_pwren: lt8668-pwren {
			rockchip,pins = <4 RK_PB6 RK_FUNC_GPIO &pcfg_pull_none>;
		};
	};

	pcie {
		pcie2_1_rst: pcie2-1-rst {
			rockchip,pins = <1 RK_PA7 RK_FUNC_GPIO &pcfg_pull_none>;
		};
	};

	sdio-pwrseq {
		wifi_enable_h: wifi-enable-h {
			rockchip,pins = <0 RK_PC4 RK_FUNC_GPIO &pcfg_pull_none>;
		};
	};

	sdmmc {
		/* GPIO0_B7 作为 SD 电源使能（低有效）：官方 5.10 dtb 为 func0 + pull-up */
		sd_s0_pwr: sd-s0-pwr {
			rockchip,pins = <0 RK_PB7 RK_FUNC_GPIO &pcfg_pull_up>;
		};
	};

	usb-typec {
		typec5v_pwren: typec5v-pwren {
			rockchip,pins = <4 RK_PA1 RK_FUNC_GPIO &pcfg_pull_none>;
		};

		usbc0_int: usbc0-int {
			rockchip,pins = <0 RK_PD3 RK_FUNC_GPIO &pcfg_pull_up>;
		};
	};

	vcc5v0 {
		vcc5v0_peripherals_en: vcc5v0-peripherals-en {
			rockchip,pins = <3 RK_PD5 RK_FUNC_GPIO &pcfg_pull_none>;
		};
	};
};

/* ==================== RGA3（两个核心 + 各自 IOMMU） ====================
 * 上游 mainline 没有 RGA3 节点；fnOS 的 rga3.ko 需要 rockchip,rga3_core0/1。
 * 中断/时钟/电源域取自 BSP 6.1 rk3588s.dtsi（同一 SoC）。
 */
/ {
	rga3_0: rga@fdb60000 {
		compatible = "rockchip,rga3_core0";
		reg = <0x0 0xfdb60000 0x0 0x1000>;
		interrupts = <GIC_SPI 114 IRQ_TYPE_LEVEL_HIGH 0>;
		interrupt-names = "rga3_core0_irq";
		clocks = <&cru ACLK_RGA3_0>, <&cru HCLK_RGA3_0>,
			 <&cru CLK_RGA3_0_CORE>;
		clock-names = "aclk_rga3_0", "hclk_rga3_0", "clk_rga3_0";
		power-domains = <&power RK3588_PD_RGA30>;
		iommus = <&rga3_0_mmu>;
		status = "okay";
	};

	rga3_0_mmu: iommu@fdb60f00 {
		compatible = "rockchip,rk3588-iommu", "rockchip,rk3568-iommu",
			     "rockchip,iommu-v2";
		reg = <0x0 0xfdb60f00 0x0 0x100>;
		interrupts = <GIC_SPI 114 IRQ_TYPE_LEVEL_HIGH 0>;
		interrupt-names = "rga3_0_mmu";
		clocks = <&cru ACLK_RGA3_0>, <&cru HCLK_RGA3_0>;
		clock-names = "aclk", "iface";
		power-domains = <&power RK3588_PD_RGA30>;
		#iommu-cells = <0>;
		status = "okay";
	};

	rga3_1: rga@fdb70000 {
		compatible = "rockchip,rga3_core1";
		reg = <0x0 0xfdb70000 0x0 0x1000>;
		interrupts = <GIC_SPI 115 IRQ_TYPE_LEVEL_HIGH 0>;
		interrupt-names = "rga3_core1_irq";
		clocks = <&cru ACLK_RGA3_1>, <&cru HCLK_RGA3_1>,
			 <&cru CLK_RGA3_1_CORE>;
		clock-names = "aclk_rga3_1", "hclk_rga3_1", "clk_rga3_1";
		power-domains = <&power RK3588_PD_RGA31>;
		iommus = <&rga3_1_mmu>;
		status = "okay";
	};

	rga3_1_mmu: iommu@fdb70f00 {
		compatible = "rockchip,rk3588-iommu", "rockchip,rk3568-iommu",
			     "rockchip,iommu-v2";
		reg = <0x0 0xfdb70f00 0x0 0x100>;
		interrupts = <GIC_SPI 115 IRQ_TYPE_LEVEL_HIGH 0>;
		interrupt-names = "rga3_1_mmu";
		clocks = <&cru ACLK_RGA3_1>, <&cru HCLK_RGA3_1>;
		clock-names = "aclk", "iface";
		power-domains = <&power RK3588_PD_RGA31>;
		#iommu-cells = <0>;
		status = "okay";
	};
};

/* ==================== VPU 硬解/硬编（厂商 MPP，rk_vcodec.ko） ====================
 *
 * 为什么以前不通：fnOS 内核自带厂商模块 rk_vcodec.ko（Rockchip MPP service
 * driver，/lib/modules/6.18.18-trim/updates/trim/rk_vcodec/rk_vcodec.ko，开机
 * 就 lsmod 可见），但它只匹配厂商 compatible（rockchip,mpp-service /
 * rockchip,vpu-decoder-v2 / rockchip,vpu-encoder-v2 / rockchip,rkv-decoder-v2 …）；
 * 而 mainline 6.18 的 rk3588-base.dtsi 在 fdb50000/fdb50400 上给的是
 * rockchip,rk3588-vpu121（mainline hantro 驱动，本内核没编 CONFIG_VIDEO_HANTRO）
 * ⇒ 从来没有驱动去 probe，自然没有 /dev/mpp_service，ffmpeg 的 rkmpp 硬解也起不来。
 *
 * 做法：把这两个地址改成厂商风格节点，挂到厂商的 mpp-srv 容器下；IOMMU 直接复用
 * mainline dtsi 的 vpu121_mmu（compatible = rockchip,rk3588-iommu，fnOS 的
 * rockchip-iommu 驱动是 mainline + 厂商补丁版，导出 rockchip_iommu_enable/… 接口）。
 * 同板 RGA3（rga3.ko + 同样风格的 iommu 节点）已验证这条路在本内核可用。
 *
 * 属性/中断/时钟值全部取自 BSP 6.1 rk3588s.dtsi（同一 SoC，第 4587/4609 行）。
 */
&vpu121 {
	status = "disabled";
};

/* mainline 的 av1d 节点（rockchip,rk3588-av1-vpu，mainline 无驱动）让位给
 * 下面的厂商 av1d 节点；两者同地址但节点名不同，dtc 不冲突 */
&av1d {
	status = "disabled";
};

/ {
	/* 厂商 MPP 服务的容器节点，子节点通过 rockchip,srv phandle 挂上来 */
	mpp_srv: mpp-srv {
		compatible = "rockchip,mpp-service";
		rockchip,taskqueue-count = <12>;
		rockchip,resetgroup-count = <1>;
		status = "okay";
	};

	vepu: vepu@fdb50000 {
		compatible = "rockchip,vpu-encoder-v2";
		reg = <0x0 0xfdb50000 0x0 0x400>;
		interrupts = <GIC_SPI 120 IRQ_TYPE_LEVEL_HIGH 0>;
		interrupt-names = "irq_vepu";
		clocks = <&cru ACLK_VPU>, <&cru HCLK_VPU>;
		clock-names = "aclk_vcodec", "hclk_vcodec";
		rockchip,normal-rates = <594000000>, <0>;
		assigned-clocks = <&cru ACLK_VPU>;
		assigned-clock-rates = <594000000>;
		resets = <&cru SRST_A_VPU>, <&cru SRST_H_VPU>;
		reset-names = "shared_video_a", "shared_video_h";
		rockchip,skip-pmu-idle-request;
		rockchip,disable-auto-freq;
		iommus = <&vpu121_mmu>;
		rockchip,srv = <&mpp_srv>;
		rockchip,taskqueue-node = <0>;
		rockchip,resetgroup-node = <0>;
		power-domains = <&power RK3588_PD_VDPU>;
		status = "okay";
	};

	vdpu: vdpu@fdb50400 {
		compatible = "rockchip,vpu-decoder-v2";
		reg = <0x0 0xfdb50400 0x0 0x400>;
		interrupts = <GIC_SPI 119 IRQ_TYPE_LEVEL_HIGH 0>;
		interrupt-names = "irq_vdpu";
		clocks = <&cru ACLK_VPU>, <&cru HCLK_VPU>;
		clock-names = "aclk_vcodec", "hclk_vcodec";
		rockchip,normal-rates = <594000000>, <0>;
		assigned-clocks = <&cru ACLK_VPU>;
		assigned-clock-rates = <594000000>;
		resets = <&cru SRST_A_VPU>, <&cru SRST_H_VPU>;
		reset-names = "shared_video_a", "shared_video_h";
		rockchip,skip-pmu-idle-request;
		rockchip,disable-auto-freq;
		iommus = <&vpu121_mmu>;
		rockchip,srv = <&mpp_srv>;
		rockchip,taskqueue-node = <0>;
		rockchip,resetgroup-node = <0>;
		power-domains = <&power RK3588_PD_VDPU>;
		status = "okay";
	};

	/* ---- RKVDEC0/1：HEVC/VP9 硬解（8K 解码核，经 CCU 协同） ----
	 * VDPU2 只覆盖 H.264/VP9 的一部分，HEVC 解码走 rkvdec。
	 * fnOS 的 rk_vcodec.ko 里 mpp_rkvdec2 驱动按节点名分流：
	 * 名字含 "ccu" → ccu 驱动，含 "core" → 解码核（需要 rockchip,ccu /
	 * rockchip,sram / rockchip,rcb-* 属性，缺一个就 probe 失败）。
	 * sram 分区加在 &system_sram2 下（见文件末尾附近）。
	 */
	rkvdec_ccu: rkvdec-ccu@fdc30000 {
		compatible = "rockchip,rkv-decoder-v2-ccu";
		reg = <0x0 0xfdc30000 0x0 0x100>;
		reg-names = "ccu";
		clocks = <&cru ACLK_RKVDEC_CCU>;
		clock-names = "aclk_ccu";
		assigned-clocks = <&cru ACLK_RKVDEC_CCU>;
		assigned-clock-rates = <600000000>;
		resets = <&cru SRST_A_RKVDEC_CCU>;
		reset-names = "video_ccu";
		rockchip,skip-pmu-idle-request;
		/* 1: soft ccu（任务级调度，RK3588 官方用法） */
		rockchip,ccu-mode = <1>;
		power-domains = <&power RK3588_PD_RKVDEC0>;
		status = "okay";
	};

	rkvdec0: rkvdec-core@fdc38000 {
		compatible = "rockchip,rkv-decoder-v2";
		reg = <0x0 0xfdc38100 0x0 0x400>, <0x0 0xfdc38000 0x0 0x100>;
		reg-names = "regs", "link";
		interrupts = <GIC_SPI 95 IRQ_TYPE_LEVEL_HIGH 0>;
		interrupt-names = "irq_rkvdec0";
		clocks = <&cru ACLK_RKVDEC0>, <&cru HCLK_RKVDEC0>,
			 <&cru CLK_RKVDEC0_CORE>, <&cru CLK_RKVDEC0_CA>,
			 <&cru CLK_RKVDEC0_HEVC_CA>;
		clock-names = "aclk_vcodec", "hclk_vcodec", "clk_core",
			      "clk_cabac", "clk_hevc_cabac";
		rockchip,normal-rates = <800000000>, <0>, <600000000>,
					<600000000>, <1000000000>;
		assigned-clocks = <&cru ACLK_RKVDEC0>, <&cru CLK_RKVDEC0_CORE>,
				  <&cru CLK_RKVDEC0_CA>, <&cru CLK_RKVDEC0_HEVC_CA>;
		assigned-clock-rates = <800000000>, <600000000>,
				       <600000000>, <1000000000>;
		resets = <&cru SRST_A_RKVDEC0>, <&cru SRST_H_RKVDEC0>,
			 <&cru SRST_RKVDEC0_CORE>, <&cru SRST_RKVDEC0_CA>,
			 <&cru SRST_RKVDEC0_HEVC_CA>;
		reset-names = "video_a", "video_h", "video_core",
			      "video_cabac", "video_hevc_cabac";
		rockchip,skip-pmu-idle-request;
		iommus = <&rkvdec0_mmu>;
		rockchip,srv = <&mpp_srv>;
		rockchip,ccu = <&rkvdec_ccu>;
		rockchip,core-mask = <0x00010001>;
		rockchip,task-capacity = <16>;
		rockchip,taskqueue-node = <9>;
		rockchip,sram = <&rkvdec0_sram>;
		/* rcb_iova: start and size 1M@4095M */
		rockchip,rcb-iova = <0xFFF00000 0x100000>;
		rockchip,rcb-info = <136 24576>, <137 49152>, <141 90112>,
				    <140 49152>, <139 180224>, <133 49152>,
				    <134 8192>, <135 4352>, <138 13056>,
				    <142 291584>;
		rockchip,rcb-min-width = <512>;
		power-domains = <&power RK3588_PD_RKVDEC0>;
		status = "okay";
	};

	rkvdec0_mmu: iommu@fdc38700 {
		compatible = "rockchip,rk3588-iommu", "rockchip,rk3568-iommu";
		reg = <0x0 0xfdc38700 0x0 0x40>, <0x0 0xfdc38740 0x0 0x40>;
		interrupts = <GIC_SPI 96 IRQ_TYPE_LEVEL_HIGH 0>;
		interrupt-names = "irq_rkvdec0_mmu";
		clocks = <&cru ACLK_RKVDEC0>, <&cru HCLK_RKVDEC0>;
		clock-names = "aclk", "iface";
		rockchip,disable-mmu-reset;
		#iommu-cells = <0>;
		power-domains = <&power RK3588_PD_RKVDEC0>;
		status = "okay";
	};

	rkvdec1: rkvdec-core@fdc48000 {
		compatible = "rockchip,rkv-decoder-v2";
		reg = <0x0 0xfdc48100 0x0 0x400>, <0x0 0xfdc48000 0x0 0x100>;
		reg-names = "regs", "link";
		interrupts = <GIC_SPI 97 IRQ_TYPE_LEVEL_HIGH 0>;
		interrupt-names = "irq_rkvdec1";
		clocks = <&cru ACLK_RKVDEC1>, <&cru HCLK_RKVDEC1>,
			 <&cru CLK_RKVDEC1_CORE>, <&cru CLK_RKVDEC1_CA>,
			 <&cru CLK_RKVDEC1_HEVC_CA>;
		clock-names = "aclk_vcodec", "hclk_vcodec", "clk_core",
			      "clk_cabac", "clk_hevc_cabac";
		rockchip,normal-rates = <800000000>, <0>, <600000000>,
					<600000000>, <1000000000>;
		assigned-clocks = <&cru ACLK_RKVDEC1>, <&cru CLK_RKVDEC1_CORE>,
				  <&cru CLK_RKVDEC1_CA>, <&cru CLK_RKVDEC1_HEVC_CA>;
		assigned-clock-rates = <800000000>, <600000000>,
				       <600000000>, <1000000000>;
		resets = <&cru SRST_A_RKVDEC1>, <&cru SRST_H_RKVDEC1>,
			 <&cru SRST_RKVDEC1_CORE>, <&cru SRST_RKVDEC1_CA>,
			 <&cru SRST_RKVDEC1_HEVC_CA>;
		reset-names = "video_a", "video_h", "video_core",
			      "video_cabac", "video_hevc_cabac";
		rockchip,skip-pmu-idle-request;
		iommus = <&rkvdec1_mmu>;
		rockchip,srv = <&mpp_srv>;
		rockchip,ccu = <&rkvdec_ccu>;
		rockchip,core-mask = <0x00020002>;
		rockchip,task-capacity = <16>;
		rockchip,taskqueue-node = <9>;
		rockchip,sram = <&rkvdec1_sram>;
		/* rcb_iova: start and size 1M@4094M */
		rockchip,rcb-iova = <0xFFE00000 0x100000>;
		rockchip,rcb-info = <136 24576>, <137 49152>, <141 90112>,
				    <140 49152>, <139 180224>, <133 49152>,
				    <134 8192>, <135 4352>, <138 13056>,
				    <142 291584>;
		rockchip,rcb-min-width = <512>;
		power-domains = <&power RK3588_PD_RKVDEC1>;
		status = "okay";
	};

	rkvdec1_mmu: iommu@fdc48700 {
		compatible = "rockchip,rk3588-iommu", "rockchip,rk3568-iommu";
		reg = <0x0 0xfdc48700 0x0 0x40>, <0x0 0xfdc48740 0x0 0x40>;
		interrupts = <GIC_SPI 98 IRQ_TYPE_LEVEL_HIGH 0>;
		interrupt-names = "irq_rkvdec1_mmu";
		clocks = <&cru ACLK_RKVDEC1>, <&cru HCLK_RKVDEC1>;
		clock-names = "aclk", "iface";
		rockchip,disable-mmu-reset;
		#iommu-cells = <0>;
		power-domains = <&power RK3588_PD_RKVDEC1>;
		status = "okay";
	};

	/* ---- AV1 硬解（8K AV1 decoder 核）—— 当前禁用 ----
	 * 可行部分：节点写对后 rk_vcodec.ko 能 probe（dmesg 会出
	 * "rk_iommu fdca0000.iommu: av1d iommu enabled"、
	 * "mpp_av1dec fdc70000.av1d: probing start/finish"，
	 * /proc/mpp_service/supports-device 会多出 DEVICE[4]:AV1DEC）。
	 * 不可行部分：fnOS 6.18 内核对 AV1D 的 dma-buf 映射会失败：
	 *   mpp_dma_import_fd: dma_buf_map_attachment ... failed(-22)
	 *   rk_vcodec: mpp_process_request: can not import fd
	 *   mpp_av1dec: no memory region mapped
	 * kprobe 显示 av1_iommu_map/iommu_map_sg 返回 -EADDRINUSE(-98)：
	 * dma-iommu 复用 IOVA 时 AV1D 硬件页表里仍有旧 PTE（页表在所有
	 * domain 间共用、unmap 未清干净），是内核侧合并 av1d iommu 的问题，
	 * 只改 DT 修不了；去掉 iommus 直通物理地址又会任务超时。
	 * 因此这里保持厂商 BSP 默认的 disabled：AV1 解码在 fnOS 上暂不可用，
	 * 等内核侧修复后再把两个 status 改回 okay 即可（节点本身是对的）。
	 */
	av1d_vpu: av1d@fdc70000 {
		compatible = "rockchip,av1-decoder";
		reg = <0x0 0xfdc70000 0x0 0x800>, <0x0 0xfdc80000 0x0 0x400>,
		      <0x0 0xfdc90000 0x0 0x400>;
		reg-names = "vcd", "cache", "afbc";
		interrupts = <GIC_SPI 108 IRQ_TYPE_LEVEL_HIGH 0>,
			     <GIC_SPI 107 IRQ_TYPE_LEVEL_HIGH 0>,
			     <GIC_SPI 106 IRQ_TYPE_LEVEL_HIGH 0>;
		interrupt-names = "irq_av1d", "irq_cache", "irq_afbc";
		clocks = <&cru ACLK_AV1>, <&cru PCLK_AV1>;
		clock-names = "aclk_vcodec", "hclk_vcodec";
		rockchip,normal-rates = <400000000>, <400000000>;
		assigned-clocks = <&cru ACLK_AV1>, <&cru PCLK_AV1>;
		assigned-clock-rates = <400000000>, <400000000>;
		resets = <&cru SRST_A_AV1>, <&cru SRST_P_AV1>;
		reset-names = "video_a", "video_h";
		rockchip,skip-pmu-idle-request;
		iommus = <&av1d_mmu>;
		rockchip,srv = <&mpp_srv>;
		rockchip,taskqueue-node = <11>;
		power-domains = <&power RK3588_PD_AV1>;
		status = "disabled";
	};

	av1d_mmu: iommu@fdca0000 {
		compatible = "rockchip,iommu-av1d";
		reg = <0x0 0xfdca0000 0x0 0x600>;
		interrupts = <GIC_SPI 109 IRQ_TYPE_LEVEL_HIGH 0>;
		interrupt-names = "irq_av1d_mmu";
		clocks = <&cru ACLK_AV1>, <&cru PCLK_AV1>;
		clock-names = "aclk", "iface";
		#iommu-cells = <0>;
		power-domains = <&power RK3588_PD_AV1>;
		status = "disabled";
	};
};

/* RKVDEC 的 RCB（行缓冲）必须落在 SoC SRAM 上；厂商 dtsi 在
 * sram@ff001000 下切了两个分区（mainline 的 system_sram2 没有子节点，补上）。
 * MPP 驱动只要子节点的 reg 区间（经父节点 ranges 转成 0xff001000 + off）。
 */
&system_sram2 {
	rkvdec0_sram: rkvdec-sram@0 {
		reg = <0x0 0x78000>;
	};

	rkvdec1_sram: rkvdec-sram@78000 {
		reg = <0x78000 0x77000>;
	};
};
